# haltium_sysctrl register map
Vendor: Nordic Semiconductor; Series: nRFHaltium; File version: 1
Registers are 32-bit, read-write, reset 0x0 unless marked. A register's access mark holds for its fields unless they carry their own. Offsets are from the block's base; [hi:lo] are bit positions; lines under a group give offsets from that group; {n}, {i} and the like mark numbered series; 'fields as' and 'values as' point back to an identical list.

## VREGMAIN_S — VREGMAIN
Base 0x5F961000
0x400 STATUS — Current voltage regulator mode
  [1:0] MODE
    0=HP (High power hysteretic mode); 1=LP (Autonomous hysteretic low power mode); 2=ULP (Refresh based ultra-Low power mode); 3=PWM (PWM mode is fixed frequency DCDC operation mode)
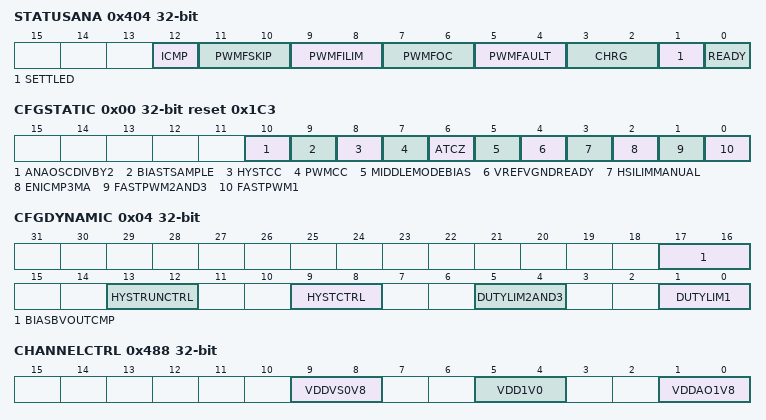
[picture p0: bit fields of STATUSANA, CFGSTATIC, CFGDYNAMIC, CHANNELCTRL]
0x404 STATUSANA ro — Status of analog module output signals
  [12] ICMP — Current value of the ICMP signal from the analog module
  [11:10] PWMFSKIP — Current value of the PWM_SKIP signal from the analog module
  [9:8] PWMFILIM — Current value of the PWM_ILIM signal from the analog module
  [7:6] PWMFOC — Current value of the PWM_OC signal from the analog module
  [5:4] PWMFAULT — Current value of the PWM_FAULT signal from the analog module
  [3:2] CHRG — Current value of the CHRG signal from the analog module
  [1] SETTLED — Current value of the SETTLED signal from the analog module
  [0] READY — Current value of the READY signal from the analog module
0x410 CONFIG group — Unspecified
  0x00 CFGSTATIC reset 0x1C3 — VREGMAIN static CFG configuration
    [all] fields
      0=Disabled (Configuration disabled); 1=Enabled (Configuration enabled)
    [10] ANAOSCDIVBY2 — Configuration for Divide OSC_ANA_RFR clock by 2
    [9] BIASTSAMPLE — Configuration for Elongate sample time for VREFs
    [8] HYSTCC — Configuration for Clamp function in HYST mode
    [7] PWMCC — Configuration for Clamp function in PWM mode
    [6] ATCZ — Configuration for Auto-zero function for P_DCCHV zero cross comparator
    [5] MIDDLEMODEBIAS — Configuration for Simple 250nA bias current generator in parallel to 10nA used for Vout comparator
    [4] VREFVGNDREADY — Configuration for VREFVGNDREADY
    [3] HSILIMMANUAL — Configuration for Override coil current limit to prog value
    [2] ENICMP3MA — Configuration for DCDC current comparator
    [1] FASTPWM2AND3 — Configuration for Faster loop 2 and 3 for PWM modulator
    [0] FASTPWM1 — Configuration for Faster loop for PWM modulator
  0x04 CFGDYNAMIC — VREGMAIN dynamic CFG configuration
    [all] fields
      0=Automatically handled by the MMI; 1=Disabled (Configuration disabled); 2=Enabled (Configuration enabled)
    [17:16] BIASBVOUTCMP — Configuration for double bias current for VOUTMCP
    [13:12] HYSTRUNCTRL — Configuration for Hysteresis feedback on MBIAS_CORE
    [9:8] HYSTCTRL — Configuration for Hysteresis 8mV (default is 4mV when disabled)
    [5:4] DUTYLIM2AND3 — Configuration for PWM modulator that limits the maximum dutycycle
    [1:0] DUTYLIM1 — Configuration for PWM modulator that limits the maximum dutycycle
0x440 TRIM group — Unspecified
  0x00 BIASIBPP — IBPP current trimming
    [2:0] VAL — Bias trim value
      0=Normal trim value; 1=The trim value is 23 percent; 2=The trim value is 54 percent; 3=The trim value is 98 percent; 4=ValNeg51 (The trim value is -51 percent); 5=ValNeg42 (The trim value is -42 percent); 6=ValNeg31 (The trim value is -31 percent); 7=ValNeg18 (The trim value is -18 percent)
  0x04 BIASIBPSR — IBPSR current and VREF voltage trimming
    [4:0] VAL — Bias trim value
  0x08 VDDAO1V8HYSTOUTPUT — VDD_AO_1V8 hysteretic (HYST) output voltage trimming
    [3:0] VAL — Trim value
  0x0C VDDAO1V8PWMOUTPUT reset 0x3 — VDD_AO_1V8 PWM output voltage trimming
    [2:0] VAL — Trim value
  0x10 VDD1V0HYSTOUTPUT — VDD_1V0 hysteretic (HYST) output voltage trimming
    [3:0] VAL — Trim value
  0x14 VDDVS0V8HYSTOUTPUT — VDD_VS_0V8 hysteretic (HYST) output voltage trimming
    [3:0] VAL — Trim value
  0x18 VDDVS0V8PWMOUTPUT reset 0x3 — VDD_VS_0V8 PWM output voltage trimming
    [2:0] VAL — Trim value
  0x1C VDD1V0PWMOUTPUT reset 0x3 — VDD_1V0 PWM output voltage trimming
    [2:0] VAL — Voltage value
  0x20 ZCROSS — Zero cross detector trimming
    [3:0] VAL — Trim value
  0x24 HSILIM — HS current limiter trimming
    [2:0] VAL — Trim value
  0x28 ICMP — DCDC output current comparator trimming
    [1:0] VAL — Trim value
      0=DCDC output current comparator trim 0 percent; 1=DCDC output current comparator trim 25 percent; 2=ValNeg50 (DCDC output current comparator trim -50 percent); 3=ValNeg25 (DCDC output current comparator trim -25 percent)
0x480 MIRROR reset 0x1 — Enable LOCK for mirrored registers
  [0] LOCK — Lock for mirrored registers
    0=Disabled (Lock disabled); 1=Enabled (Lock enabled)
0x484 PWRUPCTRL — Power up control
  [1:0] CTRL
    0=Automatically handled by the MMI; 1=PowerUp; 2=PowerDown
0x488 CHANNELCTRL — Channel control
  [all] fields
    0=Automatically handled by the MMI; 1=Enable channel; 2=Disable channel
  [9:8] VDDVS0V8 — Enable VDDVS0V8 channel (CH3)
  [5:4] VDD1V0 — Enable VDD1V0 channel (CH2)
  [1:0] VDDAO1V8 — Enable VDDAO1V8 channel (CH1)
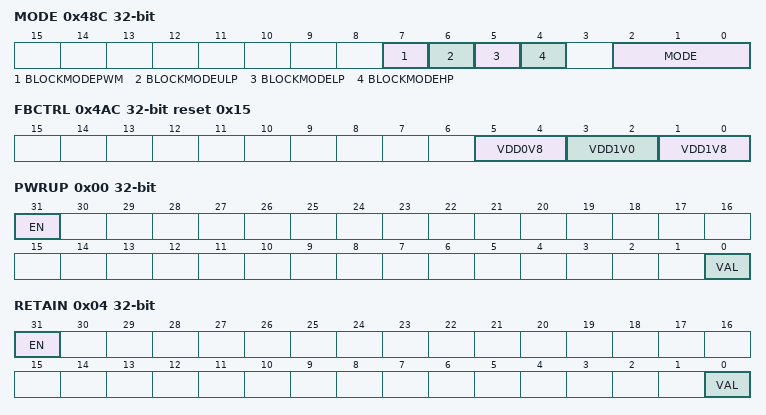
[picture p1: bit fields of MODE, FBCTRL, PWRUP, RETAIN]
0x48C MODE — Voltage regulator mode
  [7] BLOCKMODEPWM — Block PWM mode while in MODE = Auto
    0=NotBlocked (Mode not blocked); 1=Blocked (Mode blocked)
  [6] BLOCKMODEULP — Block ULP mode while in MODE = Auto
    0=NotBlocked (Mode not blocked); 1=Blocked (Mode blocked)
  [5] BLOCKMODELP — Block LP mode while in MODE = Auto
    0=NotBlocked (Mode not blocked); 1=Blocked (Mode blocked)
  [4] BLOCKMODEHP — Block HP mode while in MODE = Auto
    0=NotBlocked (Mode not blocked); 1=Blocked (Mode blocked)
  [2:0] MODE
    0=Automatically handled by the MMI; 1=HP (High power hysteretic mode); 2=LP (Autonomous hysteretic low power mode); 3=ULP (Refresh based ultra-Low power mode); 4=PWM (PWM mode is fixed frequency DCDC operation mode)
0x490 VDDAO1V8OUTPUT reset 0x2 — VDD_AO_1V8 output voltage
  [2:0] VAL — Voltage value
0x494 VDDAO1V8LPOUTPUT reset 0x2 — VDD_AO_1V8 Low Power output voltage
  [2:0] VAL — Voltage value
0x498 VDD1V0OUTPUT reset 0x17 — VDD_1V0 output voltage
  [5:0] VAL — Voltage value
0x49C VDD1V0LPOUTPUT reset 0x17 — VDD_1V0 LP output voltage
  [5:0] VAL — Voltage value
0x4A0 VDDVS0V8OUTPUT reset 0xF — VDD_VS_0V8 output voltage
  [5:0] VAL — Voltage value
0x4A4 HSILIMPROG — HS current limiter program
  [1:0] VAL — HS current limiter value
    0=Val150mA (Current limit to 150mA); 1=Val250mA (Current limit to 250mA); 2=Val350mA (Current limit to 350mA); 3=Val450mA (Current limit to 450mA (PWM mode only))
0x4A8 PWMPROG — PWM program
  [1:0] VAL — PWM program value
    0=PWMVal0 (VDD_AO_1V8 = 1/3, VDD_1V0 = 1/3, VDD_VS_0V8 = 1/3); 1=PWMVal1 (VDD_AO_1V8 = 2/4, VDD_1V0 = 1/4, VDD_VS_0V8 = 1/4); 2=PWMVal2 (VDD_AO_1V8 = 1/4, VDD_1V0 = 2/4, VDD_VS_0V8 = 1/4); 3=PWMVal3 (VDD_AO_1V8 = 1/4, VDD_1V0 = 1/4, VDD_VS_0V8 = 2/4)
0x4AC FBCTRL reset 0x15 — Regulator feedback point control
  [5:4] VDD0V8 — VDD_0V8 feedback configuration
    0=VDDVS0V8FB (VDD_VS_0V8 feedback); 1=SEC0V8FB (SEC_0V8 feedback); 3=VDDVS0V8SEC0V8FB (VDD_VS_0V8 and SEC_0V8 feedback)
  [3:2] VDD1V0 — VDD_1V0 feedback configuration
    0=VDD1V0FB (VDD_1V0 feedback); 1=SEC1V0FB (SEC_1V0 feedback); 2=VDDSEC1V0FB (VDD_1V0 and SEC_1V0 feedback); 3=VDDAOSEC1V0FB (VDD_AO_0V8 and SEC_1V0 feedback)
  [1:0] VDD1V8 — VDD_1V8 feedback configuration
    0=VDD1V8FB (VDD_1V8 feedback); 1=SEC1V8FB (SEC_1V8 feedback); 3=VDDSEC1V8FB (VDD_1V8 and SEC_1V8 feedback)
0x500 OVERRIDE group — Unspecified
  0x00 PWRUP — Override the PWRUP signal to the analog module
    [31] EN — Enable the override
      0=Disabled (Override is disabled); 1=Enabled (Override is enabled)
    [0] VAL — Override value for the signal
  0x04 RETAIN — Override the RETAIN signal to the analog module
    fields as OVERRIDE.PWRUP
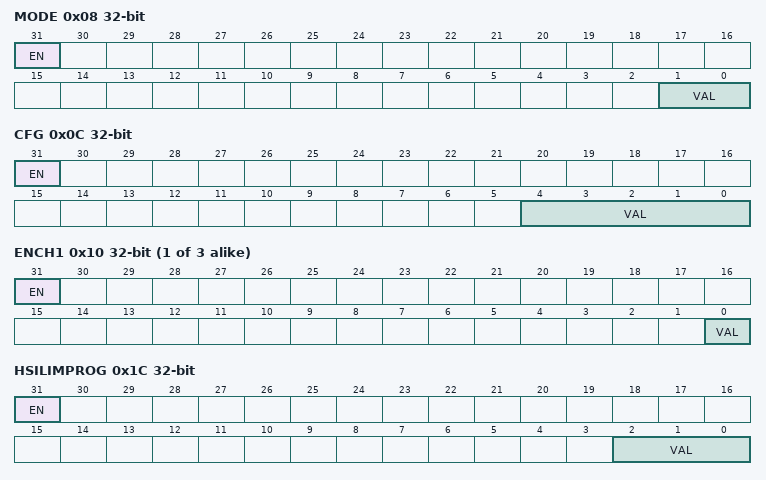
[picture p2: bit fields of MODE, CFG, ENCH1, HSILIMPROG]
  0x08 MODE — Override the MODE signal to the analog module
    [31] EN — Enable the override
      values as OVERRIDE.PWRUP.EN
    [1:0] VAL — Override value for the signal
  0x0C CFG — Override the dynamic CFG[4:0] signal to the analog module
    [31] EN — Enable the override
      values as OVERRIDE.PWRUP.EN
    [4:0] VAL — Override value for the signal
  {0xC+4j} ENCH{j} (j=1..3) — Override the EN_CH{j} signal to the analog module
    fields as OVERRIDE.PWRUP
  0x1C HSILIMPROG — Override the HSILIMPROG signal to the analog module
    [31] EN — Enable the override
      values as OVERRIDE.PWRUP.EN
    [2:0] VAL — Override value for the signal
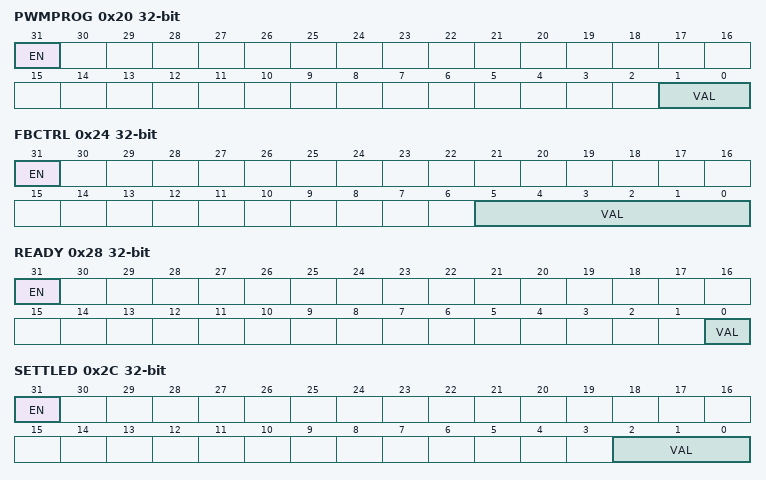
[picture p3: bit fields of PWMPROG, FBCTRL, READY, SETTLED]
  0x20 PWMPROG — Override the PWMPROG signal to the analog module
    fields as OVERRIDE.MODE
  0x24 FBCTRL — Override the FBCTRL signal to the analog module
    [31] EN — Enable the override
      values as OVERRIDE.PWRUP.EN
    [5:0] VAL — Override value for the signal
  0x28 READY — Override the READY signal from the analog module
    [31] EN — Enable the override
      values as OVERRIDE.PWRUP.EN
    [0] VAL — Current value of the signal
  0x2C SETTLED — Override the SETTLED signal from the analog module
    [31] EN — Enable the override
      values as OVERRIDE.PWRUP.EN
    [2:0] VAL — Current value of the signal
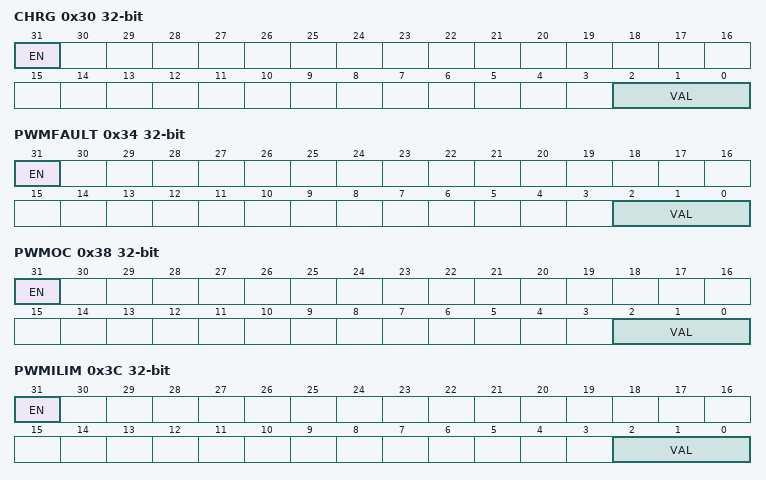
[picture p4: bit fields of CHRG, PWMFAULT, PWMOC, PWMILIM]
  0x30 CHRG — Override the CHRG signal from the analog module
    fields as OVERRIDE.SETTLED
  0x34 PWMFAULT — Override the PWM_FAULT signal from the analog module
    fields as OVERRIDE.SETTLED
  0x38 PWMOC — Override the PWM_OC signal from the analog module
    fields as OVERRIDE.SETTLED
  0x3C PWMILIM — Override the PWM_ILIM signal from the analog module
    fields as OVERRIDE.SETTLED
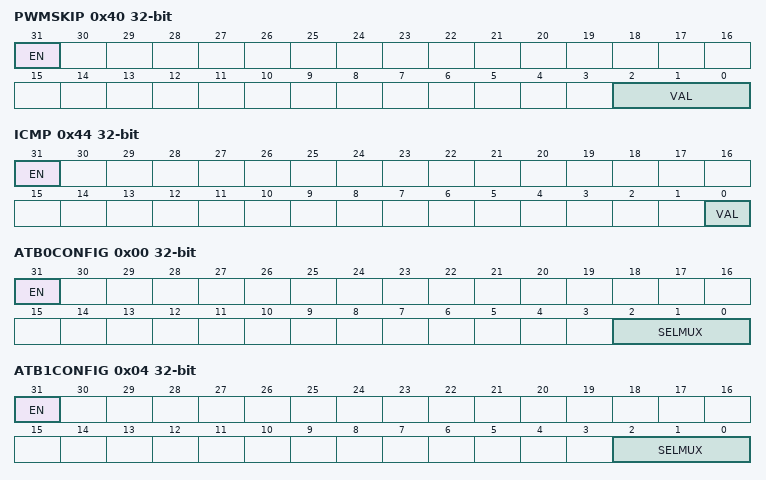
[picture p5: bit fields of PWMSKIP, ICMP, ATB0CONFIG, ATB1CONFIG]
  0x40 PWMSKIP — Override the PWM_SKIP signal from the analog module
    fields as OVERRIDE.SETTLED
  0x44 ICMP — Override the ICMP signal from the analog module
    fields as OVERRIDE.READY
0x600 DFT group — Unspecified
  0x00 ATB0CONFIG — Analog Test Bus 0 (ATB0) configuration
    [31] EN — Enable the analog test bus
      0=Disabled (Analog test bus is disabled); 1=Enabled (Analog test bus is enabled)
    [2:0] SELMUX — Select multiplexer for ATB0
      0=VFB0V9 (VFB_0V9 selected); 1=VFB1V0 (VFB_1V0 selected); 2=VFB0V8 (VFB_0V8 selected); 3=AVSSVGND (AVSS_VGND selected); 4=MBIASIBPP50N (MBIAS_IBPP_50N selected); 5=MBIASIBPSR8U (MBIAS_IBPSR_8U selected); 6=ATB0EXT (ATB0_EXT selected)
  0x04 ATB1CONFIG — Analog Test Bus 1 (ATB1) configuration
    [31] EN — Enable the analog test bus
      values as DFT.ATB0CONFIG.EN
    [2:0] SELMUX — Select multiplexer for ATB1
      0=VREF0V9 (VREF_0V9 selected); 1=VREF1V0 (VREF_1V0 selected); 2=VREF0V8 (VREF_0V8 selected); 3=VGNDREF5V (VGNDREF_5V selected); 4=MBIASVREF (MBIAS_VREF selected); 5=AVSSSIMO (AVSS_SIMO selected)
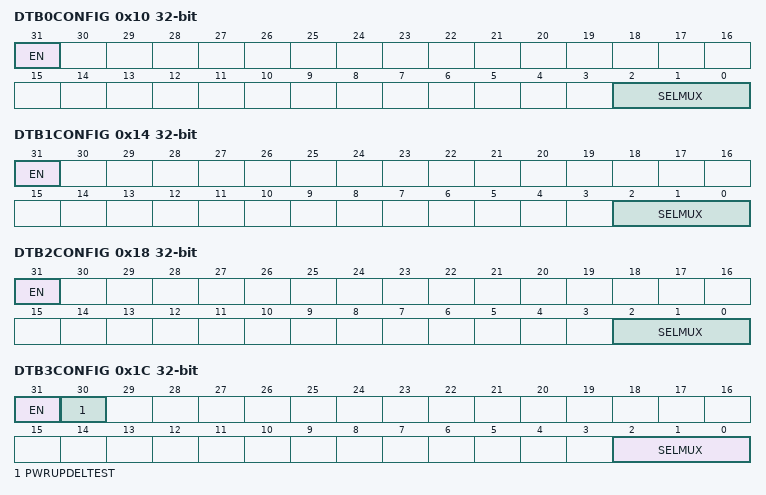
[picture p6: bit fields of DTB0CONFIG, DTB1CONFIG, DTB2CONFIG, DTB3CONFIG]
  0x10 DTB0CONFIG — Digital Test Bus 0 (DTB0) configuration
    [31] EN — Enable the digital test bus
      0=Disabled (Digital test bus is disabled); 1=Enabled (Digital test bus is enabled)
    [2:0] SELMUX — Select multiplexer for DTB0
      0=CLK (CLK selected); 1=PWMLIM11V8 (PWM_LIM1_1V8 selected); 2=REQUESTMBIAS (REQUEST_MBIAS selected); 3=PWRUPPDCCH (PWRUP_P_DCCH selected); 4=SELVOLTLP (SEL_VOLT_LP selected); 5=DRVHS (DRVHS selected); 6=MBIASSETTLED (MBIAS_SETTLED selected)
  0x14 DTB1CONFIG — Digital Test Bus 1 (DTB1) configuration
    [31] EN — Enable the digital test bus
      values as DFT.DTB0CONFIG.EN
    [2:0] SELMUX — Select multiplexer for DTB1
      0=PWMLIM2 (PWM_LIM2 selected); 1=PWRUPCH1 (PWRUPCH1 selected); 2=VOUTCMP1 (VOUTCMP1 selected); 3=PWMCMP1 (PWMCMP1 selected); 4=DRVSEC1 (DRVSEC1 selected); 5=ZCROSS (ZCROSS selected); 6=PDCCHREADY (P_DCCH_READY selected); 7=MBIASREADY (MBIAS_READY selected)
  0x18 DTB2CONFIG — Digital Test Bus 2 (DTB2) configuration
    [31] EN — Enable the digital test bus
      values as DFT.DTB0CONFIG.EN
    [2:0] SELMUX — Select multiplexer for DTB2
      0=PWRUPPWM (PWRUP_PWM selected); 1=PWRUPCH2 (PWRUPCH2 selected); 2=VOUTCMP3 (VOUTCMP3 selected); 3=PWMCMP2 (PWMCMP2 selected); 4=DRVSEC2 (DRVSEC2 selected); 5=HSLIM (HSLIM selected); 6=DRVLS (DRVLS selected); 7=IBPPREADY (IBPP_READY selected)
  0x1C DTB3CONFIG — Digital Test Bus 3 (DTB3) configuration
    [31] EN — Enable the digital test bus
      values as DFT.DTB0CONFIG.EN
    [30] PWRUPDELTEST — Enable the PWRUP delay test circuit
      0=Disabled (PWRUP delay test circuit is disabled); 1=Enabled (PWRUP delay test circuit is enabled)
    [2:0] SELMUX — Select multiplexer for DTB3
      0=PWMLIM31V8 (PWM_LIM1_1V8 selected); 1=PWRUPCH3 (PWRUPCH3 selected); 2=VOUTCMP2 (VOUTCMP2 selected); 3=PWMCMP3 (PWMCMP3 selected); 4=DRVSEC3 (DRVSEC3 selected); 5=SECREADY (SECREADY selected); 6=PWRUPHYST (PWRUP_HYST selected)
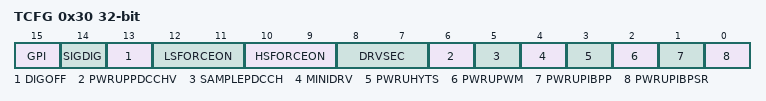
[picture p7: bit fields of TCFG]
  0x30 TCFG — Test mode configuration
    [15] GPI — Enable GPI (PUEDO PWM)
      0=Disabled (GPI disabled); 1=Enabled (GPI enabled)
    [14] SIGDIG — Enable SIGDIG
      0=Disabled (SIGDIG disabled); 1=Enabled (SIGDIG enabled)
    [13] DIGOFF — Enable DIGOFF
      0=Disabled (DIGOFF disabled); 1=Enabled (DIGOFF enabled)
    [12:11] LSFORCEON — Enable LS force on
      0=Normal mode; 1=LS force off-zx gating; 2=GPI; 3=LSforceon
    [10:9] HSFORCEON — Enable HS force on
      0=Normal mode; 1=HSILIM (HS force on HSILIM gating); 2=GPI; 3=HSforceon
    [8:7] DRVSEC — Select DRVSEC
      0=Normal mode, DRVSEC2 in reset; 1=DRVSEC1 selected; 2=DRVSEC2 selected; 3=OFF
    [6] PWRUPPDCCHV — Enable mux PWRUP_P_DCCHV
      0=Disabled (PWRUPPDCCHV disabled); 1=Enabled (PWRUPPDCCHV enabled)
    [5] SAMPLEPDCCH — Sample P_DCCH by ready
      0=Disabled (Sample P_DCCH disabled); 1=Enabled (Sample P_DCCH enabled)
    [4] MINIDRV — Enable MINIDRV
      0=Disabled (MINIDRV disabled); 1=Enabled (MINIDRV enabled)
    [3] PWRUHYTS — Enable PWRUP_HYST
      0=Disabled (PWRUP_HYST disabled); 1=Enabled (PWRUP_HYST enabled)
    [2] PWRUPWM — Enable PWRUP_PWM
      0=Disabled (PWRUP_PWM disabled); 1=Enabled (PWRUP_PWM enabled)
    [1] PWRUPIBPP — Enable PWRUP_IBPP
      0=Disabled (PWRUP_IBPP disabled); 1=Enabled (PWRUP_IBPP enabled)
    [0] PWRUPIBPSR — Enable PWRUP_IBPSR
      0=Disabled (PWRUP_IBPSR disabled); 1=Enabled (PWRUP_IBPSR enabled)
